# Z20K14xM register map
Vendor: Zhixin Semiconductor; Series: Z20K14xM; File version: 0.1.0
CPU: CM4 r0p1, little endian, no MPU, FPU, 4 interrupt priority bits
Registers are 32-bit, read-write, reset 0x0 unless marked. A register's access mark holds for its fields unless they carry their own. Offsets are from the block's base; [hi:lo] are bit positions; {n}, {i} and the like mark numbered series.

## SCM
Base 0x40048000
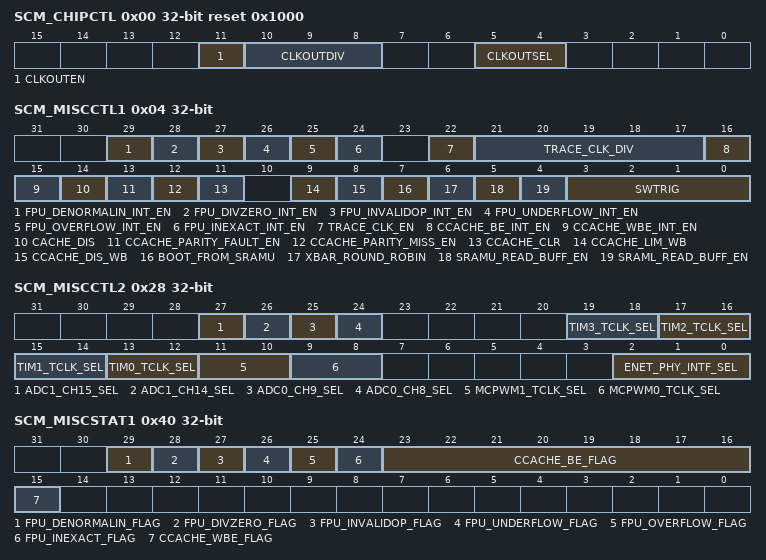
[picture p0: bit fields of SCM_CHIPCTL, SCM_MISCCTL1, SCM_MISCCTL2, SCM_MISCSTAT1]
0x00 SCM_CHIPCTL reset 0x1000 — Chip Control register (SCM_CHIPCTL)
  [11] CLKOUTEN — CLKOUT enable
  [10:8] CLKOUTDIV — CLKOUT Divide Ratio
  [5:4] CLKOUTSEL — CLKOUT Source selection
0x04 SCM_MISCCTL1 — Misc Control register 1(SCM_MISCCTL1)
  [29] FPU_DENORMALIN_INT_EN — fpu denormain interrupt enable
  [28] FPU_DIVZERO_INT_EN — fpu divzero interrupt enable
  [27] FPU_INVALIDOP_INT_EN — fpu invalidop interrupt enable
  [26] FPU_UNDERFLOW_INT_EN — fpu underflow interrupt enable
  [25] FPU_OVERFLOW_INT_EN — fpu overflow interrupt enable
  [24] FPU_INEXACT_INT_EN — fpu inexat interrupt enable
  [22] TRACE_CLK_EN — trace clock output enable
  [21:17] TRACE_CLK_DIV — trace clock divider
  [16] CCACHE_BE_INT_EN — cache bit error interrupt enable
  [15] CCACHE_WBE_INT_EN — cache write buffer error interrupt enable
  [14] CACHE_DIS — cache disable control bit
  [13] CCACHE_PARITY_FAULT_EN — cache parity fault enable
  [12] CCACHE_PARITY_MISS_EN — cache parity miss enable
  [11] CCACHE_CLR — active high clears cache
  [9] CCACHE_LIM_WB — write buffer limit
  [8] CCACHE_DIS_WB — write buffer disable
  [7] BOOT_FROM_SRAMU — Enable boot from sramu
  [6] XBAR_ROUND_ROBIN — Software Trigger to TMU
  [5] SRAMU_READ_BUFF_EN — Software Trigger to TMU
  [4] SRAML_READ_BUFF_EN — Software Trigger to TMU
  [3:0] SWTRIG — Software Trigger to TMU
0x28 SCM_MISCCTL2 — Misc Control register 2(SCM_MISCCTL2)
  [27] ADC1_CH15_SEL — ADC1 channel 15 mux select
  [26] ADC1_CH14_SEL — ADC1 channel 14 mux select
  [25] ADC0_CH9_SEL — ADC0 channel 9 mux select
  [24] ADC0_CH8_SEL — ADC0 channel 8 mux select
  [2n+13:2n+12] TIM{n}_TCLK_SEL (n=0..3) — TIM{n} external input clock select
  [11:10] MCPWM1_TCLK_SEL — MCPWM1 external input clock select
  [9:8] MCPWM0_TCLK_SEL — MCPWM0 external input clock select
  [2:0] ENET_PHY_INTF_SEL — ENET phy select
0x40 SCM_MISCSTAT1 — Misc Status register 1(SCM_MISCSTAT1)
  [29] FPU_DENORMALIN_FLAG
  [28] FPU_DIVZERO_FLAG
  [27] FPU_INVALIDOP_FLAG
  [26] FPU_UNDERFLOW_FLAG
  [25] FPU_OVERFLOW_FLAG
  [24] FPU_INEXACT_FLAG
  [23:16] CCACHE_BE_FLAG — cache bit error flag
  [15] CCACHE_WBE_FLAG — cache write buffer error flag
0x44 SCM_MISCDATA1 — Misc Data register 1(SCM_MISCDATA1)
  [31:0] CACHE_BE_ADDR — Reserved
0x48 SCM_MISCDATA2 — Misc Data register 2(SCM_MISCDATA2)
  [31:0] CACHE_BE_DATA — Reserved
0x100 SCM_CHIPOPT ro — Chip Option Register (SCM_CHIPOPT)
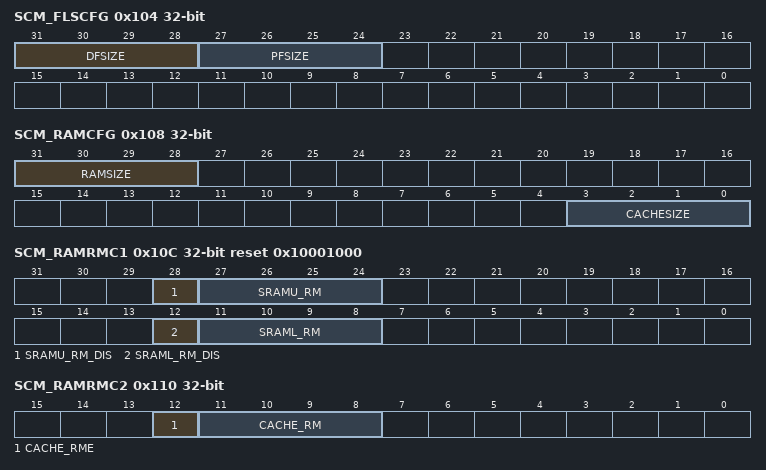
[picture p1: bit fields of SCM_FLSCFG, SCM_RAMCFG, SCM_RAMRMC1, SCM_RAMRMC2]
0x104 SCM_FLSCFG ro — Flash Configuration Register (SCM_FLSCFG)
  [31:28] DFSIZE — Data Flash Size
  [27:24] PFSIZE — Program Flash Size
0x108 SCM_RAMCFG ro — RAM Configuration Register (SCM_RAMCFG)
  [31:28] RAMSIZE — SRAM Size
  [3:0] CACHESIZE
0x10C SCM_RAMRMC1 ro reset 0x10001000 — RAM Read Margin Control Register 1(SCM_RAMRMC1)
  [28] SRAMU_RM_DIS — SRAMU read margin disable
  [27:24] SRAMU_RM — SRAMU read margin
  [12] SRAML_RM_DIS — SRAML read margin disable
  [11:8] SRAML_RM — SRAML read margin
0x110 SCM_RAMRMC2 ro — RAM Read Margin Control Register 2(SCM_RAMRMC2)
  [12] CACHE_RME — CACHE read margin enable
  [11:8] CACHE_RM — CACHE read margin
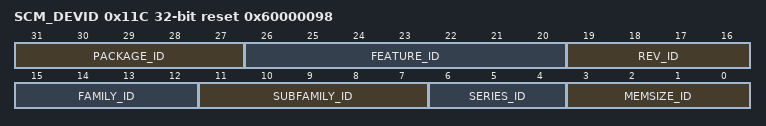
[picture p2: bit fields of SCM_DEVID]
0x11C SCM_DEVID ro reset 0x60000098 — System Device Identification Register (SCM_SDID)
  [31:27] PACKAGE_ID — Package ID load from IFR during reset
  [26:20] FEATURE_ID — Feature ID load from IFR during reset
  [19:16] REV_ID — Revision ID load from IFR during reset
  [15:12] FAMILY_ID — Family ID load from IFR during reset
  [11:7] SUBFAMILY_ID — Sub family ID load from IFR during reset
  [6:4] SERIES_ID — Series ID load from IFR during reset
  [3:0] MEMSIZE_ID — Memory size ID load from IFR during reset
{0x120+4i} SCM_UNIQUE{i} ro (i=0..3) — Unique Identification Register {i} (SCM_UID{i})
  [31:0] UID_{32i+31}_{32i} — Reserved
